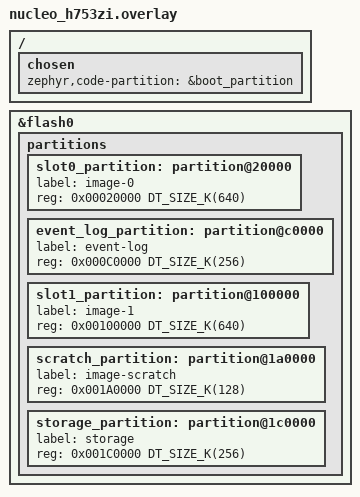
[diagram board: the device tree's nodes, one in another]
/*
 * MCUboot board overlay for nucleo_h753zi
 *
 * This must match the application's flash partition layout exactly.
 * MCUboot uses these partitions to locate slot0 (primary), slot1
 * (secondary), and scratch areas.
 *
 * Applied automatically by sysbuild from:
 *   sysbuild/mcuboot/boards/nucleo_h753zi.overlay
 *
 * Flash layout (must match boards/nucleo_h753zi.overlay):
 *   0x08000000  boot_partition       128 KB  (MCUboot)
 *   0x08020000  slot0_partition      640 KB  (primary app image)
 *   0x080C0000  event_log_partition  256 KB  (FCB ring, app-only)
 *   0x08100000  slot1_partition      640 KB  (secondary / upgrade image)
 *   0x081A0000  scratch_partition    128 KB  (MCUboot swap scratch)
 *   0x081C0000  storage_partition    256 KB  (ZMS persistent settings)
 */

/*
 * Link MCUboot itself to the boot partition (0x08000000), not slot0.
 * The base board DTS has: chosen { zephyr,code-partition = &slot0_partition; }
 * which would put MCUboot at 0x08020000 — wrong. MCUboot lives at 0x08000000.
 */
/ {
    chosen {
        zephyr,code-partition = &boot_partition;
    };
};

/* Delete the base board's default partition nodes */
&flash0 {
    partitions {
        /delete-node/ partition@20000;  /* old slot0: 256 KB */
        /delete-node/ partition@60000;  /* old slot1: 384 KB */
        /delete-node/ partition@c0000;  /* old storage: 256 KB */

        /* Primary app image: 640 KB (5 x 128 KB sectors) */
        slot0_partition: partition@20000 {
            label = "image-0";
            reg = <0x00020000 DT_SIZE_K(640)>;
        };

        /* Event log FCB ring: 256 KB (tail of bank 1) */
        event_log_partition: partition@c0000 {
            label = "event-log";
            reg = <0x000C0000 DT_SIZE_K(256)>;
        };

        /* Secondary / upgrade image: 640 KB (bank 2 start) */
        slot1_partition: partition@100000 {
            label = "image-1";
            reg = <0x00100000 DT_SIZE_K(640)>;
        };

        /* MCUboot swap scratch: 128 KB */
        scratch_partition: partition@1a0000 {
            label = "image-scratch";
            reg = <0x001A0000 DT_SIZE_K(128)>;
        };

        /* ZMS persistent settings: 256 KB (outside MCUboot swap area) */
        storage_partition: partition@1c0000 {
            label = "storage";
            reg = <0x001C0000 DT_SIZE_K(256)>;
        };
    };
};
